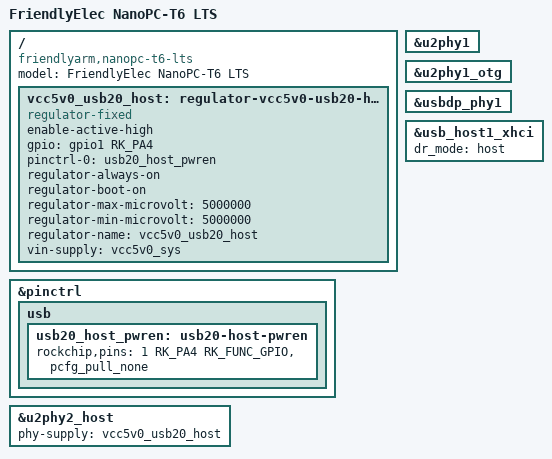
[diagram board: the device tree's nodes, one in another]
// SPDX-License-Identifier: (GPL-2.0+ OR MIT)
/*
 * Copyright (c) 2021 Rockchip Electronics Co., Ltd.
 * Copyright (c) 2023 Thomas McKahan
 * Copyright (c) 2024 Linaro Ltd.
 *
 */

/dts-v1/;

#include "rk3588-nanopc-t6.dtsi"

/ {
	model = "FriendlyElec NanoPC-T6 LTS";
	compatible = "friendlyarm,nanopc-t6-lts", "rockchip,rk3588";

	/* provide power for on-board USB 2.0 hub */
	vcc5v0_usb20_host: regulator-vcc5v0-usb20-host {
		compatible = "regulator-fixed";
		enable-active-high;
		gpio = <&gpio1 RK_PA4 GPIO_ACTIVE_HIGH>;
		pinctrl-0 = <&usb20_host_pwren>;
		pinctrl-names = "default";
		regulator-always-on;
		regulator-boot-on;
		regulator-max-microvolt = <5000000>;
		regulator-min-microvolt = <5000000>;
		regulator-name = "vcc5v0_usb20_host";
		vin-supply = <&vcc5v0_sys>;
	};
};

&pinctrl {
	usb {
		usb20_host_pwren: usb20-host-pwren {
			rockchip,pins = <1 RK_PA4 RK_FUNC_GPIO &pcfg_pull_none>;
		};
	};
};

&u2phy1 {
	status = "okay";
};

&u2phy1_otg {
	status = "okay";
};

&u2phy2_host {
	phy-supply = <&vcc5v0_usb20_host>;
};

&usbdp_phy1 {
	status = "okay";
};

&usb_host1_xhci {
	dr_mode = "host";
	status = "okay";
};
